AUTOSAR XML (schema 4-2-2)
package /ComponentTypes
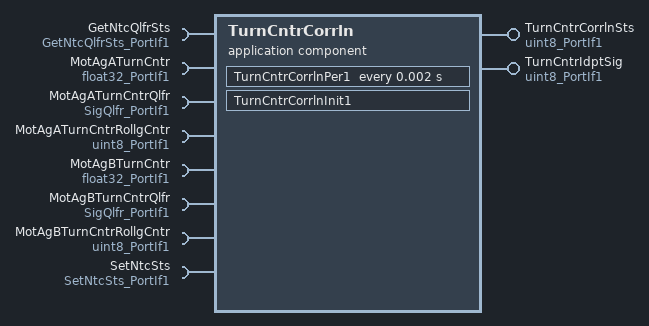
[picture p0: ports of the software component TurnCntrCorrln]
  application sw component type TurnCntrCorrln
    provide port TurnCntrCorrlnSts: nonqueued-sender-com-spec{data-element=Val, init-value=3}, provided-interface=uint8_PortIf1
    provide port TurnCntrIdptSig: nonqueued-sender-com-spec{data-element=Val, init-value=2}, provided-interface=uint8_PortIf1
    8 x require port:
      GetNtcQlfrSts: client-com-spec=Oper, required-interface=GetNtcQlfrSts_PortIf1
      MotAgATurnCntr: nonqueued-receiver-com-spec{data-element=Val, filter=data-filter-type=ALWAYS, init-value=0}, required-interface=float32_PortIf1
      MotAgATurnCntrQlfr: nonqueued-receiver-com-spec{data-element=Val, filter=data-filter-type=ALWAYS, init-value=0}, required-interface=SigQlfr_PortIf1
      MotAgATurnCntrRollgCntr: nonqueued-receiver-com-spec{data-element=Val, filter=data-filter-type=ALWAYS, init-value=0}, required-interface=uint8_PortIf1
      MotAgBTurnCntr: nonqueued-receiver-com-spec{data-element=Val, filter=data-filter-type=ALWAYS, init-value=0}, required-interface=float32_PortIf1
      MotAgBTurnCntrQlfr: nonqueued-receiver-com-spec{data-element=Val, filter=data-filter-type=ALWAYS, init-value=0}, required-interface=SigQlfr_PortIf1
      MotAgBTurnCntrRollgCntr: nonqueued-receiver-com-spec{data-element=Val, filter=data-filter-type=ALWAYS, init-value=0}, required-interface=uint8_PortIf1
      SetNtcSts: client-com-spec=Oper, required-interface=SetNtcSts_PortIf1
    behavior TurnCntrCorrln_InternalBehavior
      ar-typed-per-instance-memorys:
        4 x data, all with sw-calibration-access=READ-ONLY, type=uint8:
          MotAgATurnCntrRollgCntPrev
          MotAgATurnCntrStallCntPrev
          MotAgBTurnCntrRollgCntPrev
          MotAgBTurnCntrStallCntPrev
      init event TurnCntrCorrln_InitEvent: start-on-event=TurnCntrCorrlnInit1
      timing event TMT_TurnCntrCorrlnPer1: start-on-event=TurnCntrCorrlnPer1, period=0.002
      runnable TurnCntrCorrlnInit1
      runnable TurnCntrCorrlnPer1
        data-receive-point-by-arguments:
          6 x access:
            REC_MotAgATurnCntr_Val: accessed-variable=MotAgATurnCntr.Val
            REC_MotAgATurnCntrQlfr_Val: accessed-variable=MotAgATurnCntrQlfr.Val
            REC_MotAgATurnCntrRollgCntr_Val: accessed-variable=MotAgATurnCntrRollgCntr.Val
            REC_MotAgBTurnCntr_Val: accessed-variable=MotAgBTurnCntr.Val
            REC_MotAgBTurnCntrQlfr_Val: accessed-variable=MotAgBTurnCntrQlfr.Val
            REC_MotAgBTurnCntrRollgCntr_Val: accessed-variable=MotAgBTurnCntrRollgCntr.Val
        data-send-points:
          access SEND_TurnCntrCorrlnSts_Val: accessed-variable=TurnCntrCorrlnSts.Val
          access SEND_TurnCntrIdptSig_Val: accessed-variable=TurnCntrIdptSig.Val
        sync call SC_GetNtcQlfrSts_Oper: operation=GetNtcQlfrSts.Oper, timeout=0
        sync call SC_SetNtcSts_Oper: operation=SetNtcSts.Oper, timeout=0
  swc implementation TurnCntrCorrln_Implementation: behavior=TurnCntrCorrln_InternalBehavior
    code-descriptors:
      code Default: artifact-descriptors=autosar-engineering-object={short-label=Default, category=SWSRC}
